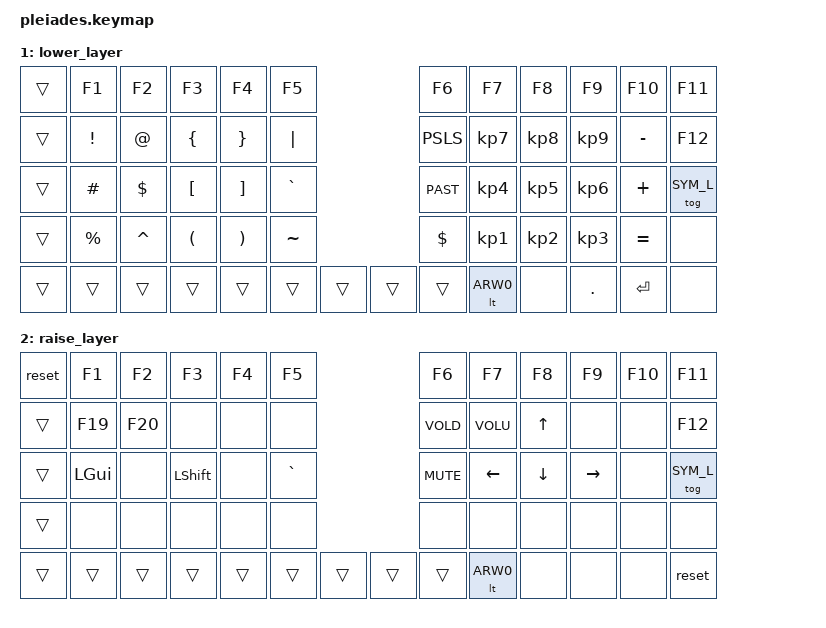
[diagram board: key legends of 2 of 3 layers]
/*
 * Copyright (c) 2021 The ZMK Contributors
 *
 * SPDX-License-Identifier: MIT
 */

#include <behaviors.dtsi>
#include <dt-bindings/zmk/keys.h>
#include <dt-bindings/zmk/bt.h>
#include <dt-bindings/zmk/ext_power.h>
#include <dt-bindings/zmk/outputs.h>

//  ----------keycodes---------- Works
#define MEH   LC(LS(LALT))

#define CTMT(keycode) &mt LCTRL keycode // Control mod tap
#define HMSF(keycode) &hm LSHIFT keycode // Shift mod tap for homerow

#define ARW0 ARW_L KP_N0
#define SYMBS SYM_L BSPC //Tap Backspace - hold Symbol Layer

#define VOLU C_VOL_UP
#define VOLD C_VOL_DN
#define MUTE C_MUTE

#define PSLS KP_SLASH
#define PAST KP_MULTIPLY
//  ----------keycodes----------

//  ----------Layers----------
#define COL_L   0
#define SYM_L   1
#define ARW_L   2
//  ----------Layers----------

&mt {
    tapping-term-ms = <200>;
 };

//------ To ADD ---------
//COMBO for caps lock
//Mouse keys or just left and right mouse click

/ {
    behaviors {
        hm: homerow_mods {
            compatible = "zmk,behavior-hold-tap";
            label = "HOMEROW_MODS";
            #binding-cells = <2>;
            tapping-term-ms = <250>;
            quick-tap-ms = <200>;
            flavor = "tap-preferred"; 
            bindings = <&kp>, <&kp>;
        };
    };

    keymap {
        compatible =  "zmk,keymap" ;

        default_layer {
// -----------------------------------------------------------------------------------------------------------------------------------------------------------
// | GRAVE   |    1    |    2    |    3    |    4    |    5    |               ---               |    6    |    7    |    8    |    9    |    0    |    -    |
// | TAB     |    Q    |    W    |    F    |    P    |    B    |               ---               |    J    |    L    |    U    |    Y    |    ;    |    =    |
// | ESC     |    A    |    R    | S[SHIFT]|    T    |    G    |               ---               |    M    |    N    | E[SHIFT]|    I    |    O    |    '    |
// | SHIFT   |    Z    |    X    |    C    |    D    |    V    |               ---               |    K    |    H    |    ,    |    .    |    /    |  SHIFT  |
// | WIN     |   ALT   |   COPY  |  PASTE  |   MEH   |BKSP[SYM]|DEL[CTRL]|     ---     |ENT[CTRL]|  SPACE  | [ARROW] |   HOME  |   END   |  PG_UP  | PG_DOWN |
            bindings = <
   &kp GRAVE  &kp N1     &kp N2     &kp N3     &kp N4     &kp N5                              &kp N6     &kp N7     &kp N8     &kp N9     &kp N0     &kp MINUS
   &kp TAB    &kp Q      &kp W      &kp F      &kp P      &kp B                               &kp J      &kp L      &kp U      &kp Y      &kp SEMI   &kp EQUAL
   &kp ESC    &kp A      &kp R      HMSF (S)   &kp T      &kp G                               &kp M      &kp N      HMSF (E)   &kp I      &kp O      &kp SQT
   &kp LSHFT  &kp Z      &kp X      &kp C      &kp D      &kp V                               &kp K      &kp H      &kp COMMA  &kp DOT    &kp FSLH   &kp RSHFT
   &kp LGUI   &kp LALT   &kp LC(C)  &kp LC(V)  &kp MEH    &lt SYMBS  CTMT(DEL)     CTMT(RET)  &kp SPACE  &mo ARW_L  &kp HOME   &kp END    &kp PG_UP  &kp PG_DN  
            >;
        };
        
        lower_layer {
// -----------------------------------------------------------------------------------------------------------------------------------------------------------
// | _______ |    F1   |    F2   |    F3   |    F4   |    F5   |               ---               |    F6   |    F7   |    F8   |    F9   |   F10   |   F11   |
// | _______ |    !    |    @    |    {    |    }    |    |    |               ---               |    /    |    7    |    8    |    9    |    -    |   F12   |
// | _______ |    #    |    $    |    [    |    ]    |    `    |               ---               |    *    |    4    |    5    |    6    |    +    | COLEMAK |
// | _______ |    %    |    ^    |    (    |    )    |    ~    |               ---               |    $    |    1    |    2    |    3    |    =    | XXXXXXX |
// | _______ | _______ | _______ | _______ | _______ | _______ | _______ |     ---     | _______ | _______ | 0[ARROW]| XXXXXXX |    .    |  ENTER  | XXXXXXX |
            bindings = <
   &trans     &kp F1     &kp F2     &kp F3     &kp F4     &kp F5                              &kp F6     &kp F7     &kp F8     &kp F9     &kp F10    &kp F11
   &trans     &kp EXCL   &kp AT     &kp LBRC   &kp RBRC   &kp PIPE                            &kp PSLS   &kp KP_N7  &kp KP_N8  &kp KP_N9  &kp MINUS  &kp F12
   &trans     &kp HASH   &kp DLLR   &kp LBKT   &kp RBKT   &kp GRAVE                           &kp PAST   &kp KP_N4  &kp KP_N5  &kp KP_N6  &kp PLUS   &tog SYM_L
   &trans     &kp PRCNT  &kp CARET  &kp LPAR   &kp RPAR   &kp TILDE                           &kp DLLR   &kp KP_N1  &kp KP_N2  &kp KP_N3  &kp EQUAL  &none
   &trans     &trans     &trans     &trans     &trans     &trans     &trans        &trans     &trans     &lt ARW0   &none      &kp DOT    &kp RET    &none
            >;
        };

        raise_layer {
// -----------------------------------------------------------------------------------------------------------------------------------------------------------
// |  RESET  |    F1   |    F2   |    F3   |    F4   |    F5   |               ---               |    F6   |    F7   |    F8   |    F9   |   F10   |   F11   |
// | _______ |   F19   |    F20  | XXXXXXX | XXXXXXX | XXXXXXX |               ---               |  VOL DN |  VOL UP |    ^    | XXXXXXX | XXXXXXX |   F12   |
// | _______ |   WIN   | XXXXXXX |  SHIFT  |  CTRL   | XXXXXXX |               ---               |   MUTE  |    <-   |    v    |   ->    | XXXXXXX | COLEMAK |
// | _______ | XXXXXXX | XXXXXXX | XXXXXXX | XXXXXXX | XXXXXXX |               ---               | XXXXXXX | XXXXXXX | XXXXXXX | XXXXXXX | XXXXXXX | XXXXXXX |
// | _______ | _______ | _______ | _______ | _______ | _______ | _______ |     ---     | _______ | _______ | [ARROW] | XXXXXXX | XXXXXXX | XXXXXXX |  RESET  |
            bindings = <
   &reset     &kp F1     &kp F2     &kp F3     &kp F4     &kp F5                              &kp F6     &kp F7     &kp F8     &kp F9     &kp F10    &kp F11
   &trans     &kp F19    &kp F20    &none      &none      &none                               &kp VOLD   &kp VOLU   &kp UP     &none      &none      &kp F12
   &trans     &kp LGUI   &none      &kp LSHIFT &none      &kp GRAVE                           &kp MUTE   &kp LEFT   &kp DOWN   &kp RIGHT  &none      &tog SYM_L
   &trans     &none      &none      &none      &none      &none                               &none      &none      &none      &none      &none      &none
   &trans     &trans     &trans     &trans     &trans     &trans     &trans        &trans     &trans     &lt ARW0   &none      &none      &none      &reset
            >;
        };
    };
};
